# STM32L4A6xx register map
File version: 1.0
Registers are 32-bit, read-write, reset 0x0 unless marked. A register's access mark holds for its fields unless they carry their own. Offsets are from the block's base; [hi:lo] are bit positions; {n}, {i} and the like mark numbered series; 'fields as' and 'values as' point back to an identical list.

## HASH
Base 0x50060400
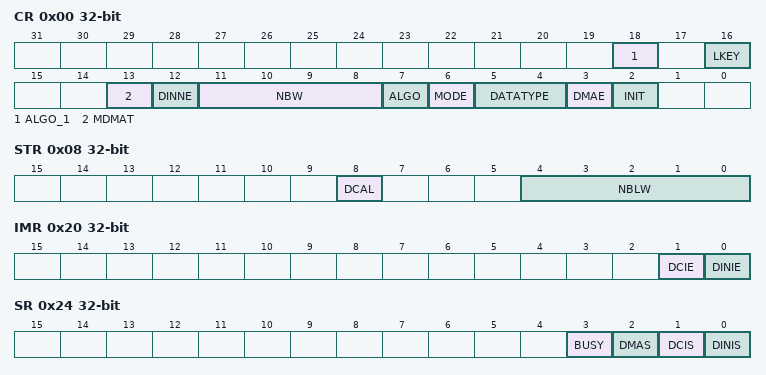
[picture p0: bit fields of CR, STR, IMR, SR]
0x00 CR — HASH control register
  [18] ALGO_1, [16] LKEY, [13] MDMAT, [12] DINNE, [11:8] NBW, [7] ALGO, [6] MODE, [5:4] DATATYPE, [3] DMAE, [2] INIT
0x04 DIN — HASH data input register
0x08 STR — HASH start register
  [8] DCAL, [4:0] NBLW
{0xC+4i} HR{i} (i=0..4) — HASH digest registers
0x20 IMR — HASH interrupt enable register
  [1] DCIE, [0] DINIE
0x24 SR — HASH status register
  [3] BUSY, [2] DMAS, [1] DCIS, [0] DINIS
{0xF8+4i} CSR{i} (i=0..53) — HASH context swap registers
{0x310+4i} DIGEST_HR{i} (i=0..7) — HASH digest registers

## RNG
Base 0x50060800
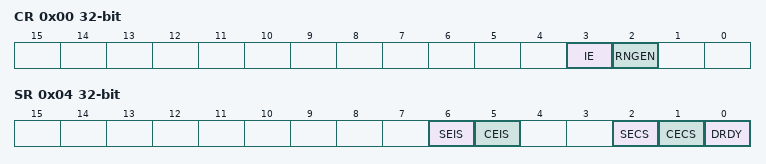
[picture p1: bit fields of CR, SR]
0x00 CR — RNG control register
  [3] IE, [2] RNGEN
0x04 SR — RNG status register
  [6] SEIS, [5] CEIS, [2] SECS, [1] CECS, [0] DRDY
0x08 DR — RNG data register

## FMC_Bank1_R — Flexible Memory Controller
Base 0xA0000000
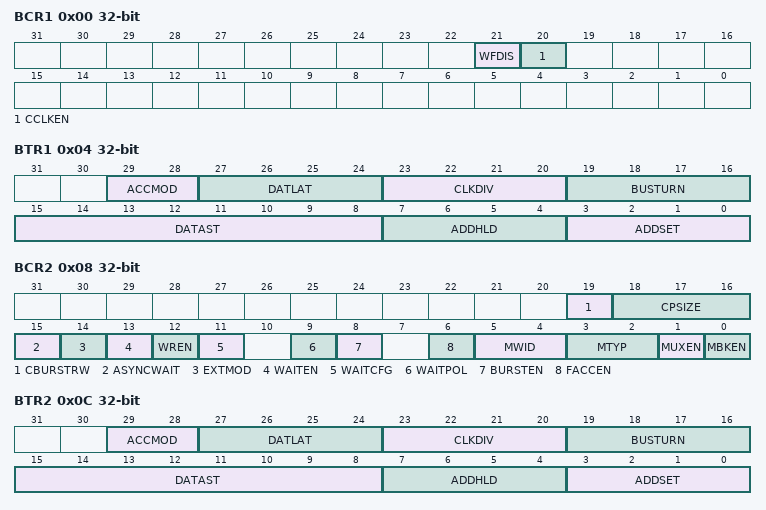
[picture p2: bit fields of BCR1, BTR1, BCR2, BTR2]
0x00 BCR1 — NOR/PSRAM chip-select control register(BCR) and chip-select timing register(BTR)
  [21] WFDIS — Write FIFO Disable
  [20] CCLKEN — Continuous clock enable
0x04 BTR1 — NOR/PSRAM chip-select control register(BCR) and chip-select timing register(BTR)
  [29:28] ACCMOD — ACCMOD[1:0] bits (Access mode)
  [27:24] DATLAT — DATLAT[3:0] bits (Data latency)
  [23:20] CLKDIV — CLKDIV[3:0] bits (Clock divide ratio)
  [19:16] BUSTURN — BUSTURN[3:0] bits (Bus turnaround phase duration)
  [15:8] DATAST — DATAST [3:0] bits (Data-phase duration)
  [7:4] ADDHLD — ADDHLD[3:0] bits (Address-hold phase duration)
  [3:0] ADDSET — ADDSET[3:0] bits (Address setup phase duration)
0x08 BCR2 — NOR/PSRAM chip-select control register(BCR) and chip-select timing register(BTR)
  [19] CBURSTRW — Write burst enable
  [18:16] CPSIZE — CRAM page size
  [15] ASYNCWAIT — Asynchronous wait
  [14] EXTMOD — Extended mode enable
  [13] WAITEN — Wait enable bit
  [12] WREN — Write enable bit
  [11] WAITCFG — Wait timing configuration
  [9] WAITPOL — Wait signal polarity bit
  [8] BURSTEN — Burst enable bit
  [6] FACCEN — Flash access enable
  [5:4] MWID — MWID[1:0] bits (Memory data bus width)
  [3:2] MTYP — MTYP[1:0] bits (Memory type)
  [1] MUXEN — Address/data multiplexing enable bit
  [0] MBKEN — Memory bank enable bit
0x0C BTR2 — NOR/PSRAM chip-select control register(BCR) and chip-select timing register(BTR)
  fields as BTR1
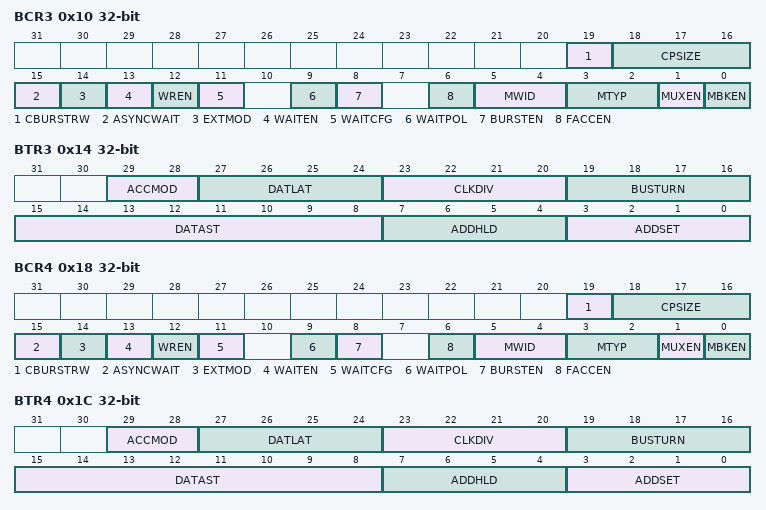
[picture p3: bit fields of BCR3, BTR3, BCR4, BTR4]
0x10 BCR3 — NOR/PSRAM chip-select control register(BCR) and chip-select timing register(BTR)
  fields as BCR2
0x14 BTR3 — NOR/PSRAM chip-select control register(BCR) and chip-select timing register(BTR)
  fields as BTR1
0x18 BCR4 — NOR/PSRAM chip-select control register(BCR) and chip-select timing register(BTR)
  fields as BCR2
0x1C BTR4 — NOR/PSRAM chip-select control register(BCR) and chip-select timing register(BTR)
  fields as BTR1

## FMC_Bank3_R — Flexible Memory Controller Bank3
Base 0xA0000080
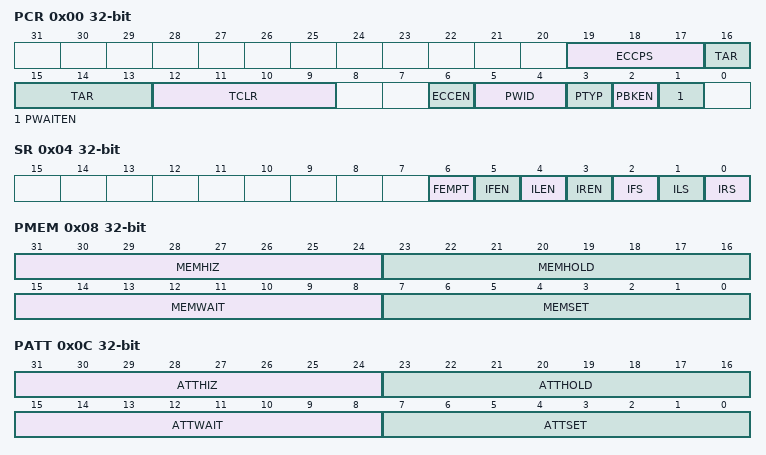
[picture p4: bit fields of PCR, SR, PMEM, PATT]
0x00 PCR — NAND Flash control register
  [19:17] ECCPS — ECCPS[1:0] bits (ECC page size)
  [16:13] TAR — TAR[3:0] bits (ALE to RE delay)
  [12:9] TCLR — TCLR[3:0] bits (CLE to RE delay)
  [6] ECCEN — ECC computation logic enable bit
  [5:4] PWID — PWID[1:0] bits (NAND Flash databus width)
  [3] PTYP — Memory type
  [2] PBKEN — NAND Flash memory bank enable bit
  [1] PWAITEN — Wait feature enable bit
0x04 SR — NAND Flash FIFO status and interrupt register
  [6] FEMPT — FIFO empty
  [5] IFEN — Interrupt Falling Edge detection Enable bit
  [4] ILEN — Interrupt Level detection Enable bit
  [3] IREN — Interrupt Rising Edge detection Enable bit
  [2] IFS — Interrupt Falling Edge status
  [1] ILS — Interrupt Level status
  [0] IRS — Interrupt Rising Edge status
0x08 PMEM — NAND Flash Common memory space timing register
  [31:24] MEMHIZ — MEMHIZ[7:0] bits (Common memory databus HiZ time)
  [23:16] MEMHOLD — MEMHOLD[7:0] bits (Common memory hold time)
  [15:8] MEMWAIT — MEMWAIT[7:0] bits (Common memory wait time)
  [7:0] MEMSET — MEMSET[7:0] bits (Common memory setup time)
0x0C PATT — NAND Flash Attribute memory space timing register
  [31:24] ATTHIZ — ATTHIZ[7:0] bits (Attribute memory databus HiZ time)
  [23:16] ATTHOLD — ATTHOLD[7:0] bits (Attribute memory hold time)
  [15:8] ATTWAIT — ATTWAIT[7:0] bits (Attribute memory wait time)
  [7:0] ATTSET — ATTSET[7:0] bits (Attribute memory setup time)
0x14 ECCR — NAND Flash ECC result registers
  [31:0] ECC — ECC result
